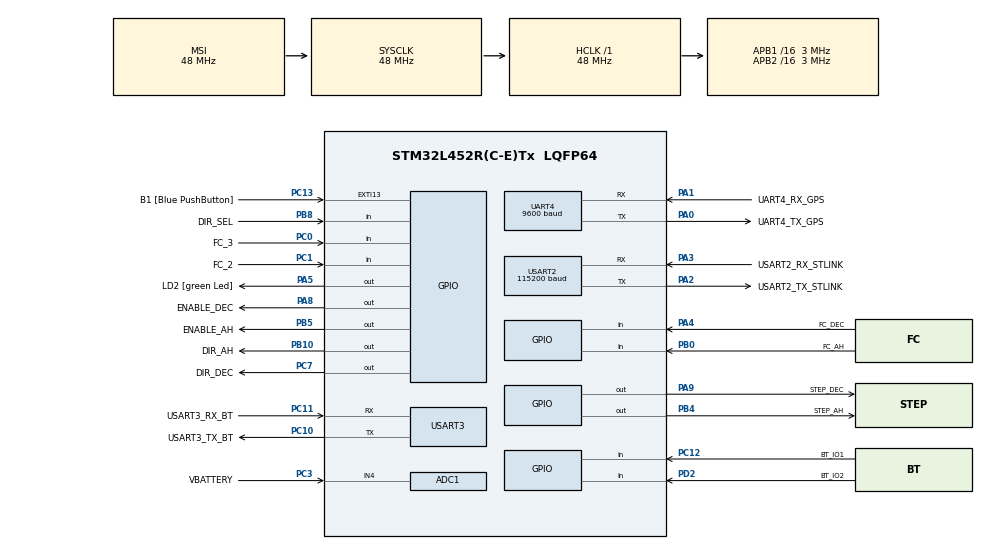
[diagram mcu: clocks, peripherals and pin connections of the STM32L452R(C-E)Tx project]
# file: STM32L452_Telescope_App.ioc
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ADC1.Channel-4\#ChannelRegularConversion=ADC_CHANNEL_4
ADC1.Channel-5\#ChannelRegularConversion=ADC_CHANNEL_TEMPSENSOR
ADC1.Channel-6\#ChannelRegularConversion=ADC_CHANNEL_VBAT
ADC1.Channel-7\#ChannelRegularConversion=ADC_CHANNEL_VREFINT
ADC1.ContinuousConvMode=DISABLE
ADC1.DMAContinuousRequests=DISABLE
ADC1.EOCSelection=ADC_EOC_SEQ_CONV
ADC1.NbrOfConversion=4
ADC1.NbrOfConversionFlag=1
ADC1.OffsetNumber-4\#ChannelRegularConversion=ADC_OFFSET_NONE
ADC1.OffsetNumber-5\#ChannelRegularConversion=ADC_OFFSET_NONE
ADC1.OffsetNumber-6\#ChannelRegularConversion=ADC_OFFSET_NONE
ADC1.OffsetNumber-7\#ChannelRegularConversion=ADC_OFFSET_NONE
ADC1.Rank-4\#ChannelRegularConversion=1
ADC1.Rank-5\#ChannelRegularConversion=2
ADC1.Rank-6\#ChannelRegularConversion=3
ADC1.Rank-7\#ChannelRegularConversion=4
ADC1.Resolution=ADC_RESOLUTION_12B
ADC1.SamplingTime-4\#ChannelRegularConversion=ADC_SAMPLETIME_640CYCLES_5
ADC1.SamplingTime-5\#ChannelRegularConversion=ADC_SAMPLETIME_92CYCLES_5
ADC1.SamplingTime-6\#ChannelRegularConversion=ADC_SAMPLETIME_92CYCLES_5
ADC1.SamplingTime-7\#ChannelRegularConversion=ADC_SAMPLETIME_92CYCLES_5
ADC1.master=1
Dma.ADC1.0.Direction=DMA_PERIPH_TO_MEMORY
Dma.ADC1.0.Instance=DMA1_Channel1
Dma.ADC1.0.MemDataAlignment=DMA_MDATAALIGN_HALFWORD
Dma.ADC1.0.MemInc=DMA_MINC_ENABLE
Dma.ADC1.0.Mode=DMA_CIRCULAR
Dma.ADC1.0.PeriphDataAlignment=DMA_PDATAALIGN_HALFWORD
Dma.ADC1.0.PeriphInc=DMA_PINC_DISABLE
Dma.ADC1.0.Priority=DMA_PRIORITY_LOW
Dma.Request0=ADC1
Mcu.Family=STM32L4
Mcu.Name=STM32L452R(C-E)Tx
Mcu.Package=LQFP64
NVIC.ADC1_IRQn=true\:0\:0\:false\:false\:true\:true\:true
NVIC.DMA1_Channel1_IRQn=true\:0\:0\:false\:false\:true\:false\:true
NVIC.PriorityGroup=NVIC_PRIORITYGROUP_4
NVIC.TIM1_BRK_TIM15_IRQn=true\:0\:0\:false\:false\:true\:true\:true
NVIC.TIM2_IRQn=true\:0\:0\:true\:false\:true\:true\:true
NVIC.UART4_IRQn=true\:3\:0\:true\:false\:true\:true\:true
NVIC.USART2_IRQn=true\:3\:0\:true\:false\:true\:true\:true
NVIC.USART3_IRQn=true\:0\:0\:false\:false\:true\:true\:true
NVIC.WWDG_IRQn=true\:0\:0\:false\:false\:true\:true\:true
PA0.GPIO_Label=UART4_TX_GPS
PA0.Mode=Asynchronous
PA0.Signal=UART4_TX
PA1.GPIO_Label=UART4_RX_GPS
PA1.Mode=Asynchronous
PA1.Signal=UART4_RX
PA13\ (JTMS/SWDIO).GPIO_Label=TMS
PA13\ (JTMS/SWDIO).Mode=Trace_Asynchronous_SW
PA13\ (JTMS/SWDIO).Signal=SYS_JTMS-SWDIO
PA14\ (JTCK/SWCLK).GPIO_Label=TCK
PA14\ (JTCK/SWCLK).Mode=Trace_Asynchronous_SW
PA14\ (JTCK/SWCLK).Signal=SYS_JTCK-SWCLK
PA2.GPIO_Label=USART2_TX_STLINK
PA2.GPIO_Mode=GPIO_MODE_AF_PP
PA2.GPIO_PuPd=GPIO_NOPULL
PA2.GPIO_Speed=GPIO_SPEED_FREQ_VERY_HIGH
PA2.Mode=Asynchronous
PA2.Signal=USART2_TX
PA3.GPIO_Label=USART2_RX_STLINK
PA3.GPIO_Mode=GPIO_MODE_AF_PP
PA3.GPIO_PuPd=GPIO_NOPULL
PA3.GPIO_Speed=GPIO_SPEED_FREQ_VERY_HIGH
PA3.Mode=Asynchronous
PA3.Signal=USART2_RX
PA4.GPIO_Label=FC_DEC
PA4.GPIO_PuPd=GPIO_PULLUP
PA4.Signal=GPIO_Input
PA5.GPIO_Label=LD2 [green Led]
PA5.GPIO_ModeDefaultOutputPP=GPIO_MODE_OUTPUT_PP
PA5.GPIO_PuPd=GPIO_NOPULL
PA5.GPIO_Speed=GPIO_SPEED_FREQ_LOW
PA5.Signal=GPIO_Output
PA8.GPIO_Label=ENABLE_DEC
PA8.Signal=GPIO_Output
PA9.GPIO_Label=STEP_DEC
PA9.Signal=GPIO_Output
PB0.GPIO_Label=FC_AH
PB0.GPIO_PuPd=GPIO_PULLUP
PB0.Signal=GPIO_Input
PB10.GPIO_Label=DIR_AH
PB10.Signal=GPIO_Output
PB3\ (JTDO/TRACESWO).GPIO_Label=SWO
PB3\ (JTDO/TRACESWO).Mode=Trace_Asynchronous_SW
PB3\ (JTDO/TRACESWO).Signal=SYS_JTDO-SWO
PB4\ (NJTRST).GPIO_Label=STEP_AH
PB4\ (NJTRST).Signal=GPIO_Output
PB5.GPIO_Label=ENABLE_AH
PB5.Signal=GPIO_Output
PB8.GPIO_Label=DIR_SEL
PB8.GPIO_PuPd=GPIO_PULLUP
PB8.Signal=GPIO_Input
PC0.GPIO_Label=FC_3
PC0.GPIO_PuPd=GPIO_PULLUP
PC0.Signal=GPIO_Input
PC1.GPIO_Label=FC_2
PC1.GPIO_PuPd=GPIO_PULLUP
PC1.Signal=GPIO_Input
PC10.GPIO_Label=USART3_TX_BT
PC10.Mode=Asynchronous
PC10.Signal=USART3_TX
PC11.GPIO_Label=USART3_RX_BT
PC11.Mode=Asynchronous
PC11.Signal=USART3_RX
PC12.GPIO_Label=BT_IO1
PC12.Signal=GPIO_Input
PC13.GPIO_Label=B1 [Blue PushButton]
PC13.GPIO_ModeDefaultEXTI=GPIO_MODE_IT_FALLING
PC13.GPIO_PuPd=GPIO_NOPULL
PC13.Signal=GPXTI13
PC14-OSC32_IN\ (PC14).Mode=LSE-External-Oscillator
PC14-OSC32_IN\ (PC14).Signal=RCC_OSC32_IN
PC15-OSC32_OUT\ (PC15).Mode=LSE-External-Oscillator
PC15-OSC32_OUT\ (PC15).Signal=RCC_OSC32_OUT
PC3.GPIO_Label=VBATTERY
PC3.Signal=ADCx_IN4
PC7.GPIO_Label=DIR_DEC
PC7.Signal=GPIO_Output
PD2.GPIO_Label=BT_IO2
PD2.Signal=GPIO_Input
PH0-OSC_IN\ (PH0).Signal=RCC_OSC_IN
PH1-OSC_OUT\ (PH1).Signal=RCC_OSC_OUT
ProjectManager.HeapSize=0x200
ProjectManager.StackSize=0x400
ProjectManager.TargetToolchain=SW4STM32
RCC.ADCFreq_Value=16000000
RCC.AHBFreq_Value=48000000
RCC.APB1CLKDivider=RCC_HCLK_DIV16
RCC.APB1Freq_Value=3000000
RCC.APB1TimFreq_Value=6000000
RCC.APB2CLKDivider=RCC_HCLK_DIV16
RCC.APB2Freq_Value=3000000
RCC.APB2TimFreq_Value=6000000
RCC.CortexFreq_Value=48000000
RCC.HCLKFreq_Value=48000000
RCC.HSE_VALUE=8000000
RCC.HSI48_VALUE=48000000
RCC.HSI_VALUE=16000000
RCC.MSIClockRange=RCC_MSIRANGE_11
RCC.MSI_VALUE=48000000
RCC.PLLR=RCC_PLLR_DIV8
RCC.PLLSAI1R=RCC_PLLR_DIV8
RCC.PLLSourceVirtual=RCC_PLLSOURCE_HSI
RCC.PREFETCH_ENABLE=1
RCC.RTCClockSelection=RCC_RTCCLKSOURCE_LSE
RCC.SYSCLKFreq_VALUE=48000000
RCC.USBFreq_Value=64000000
RCC.VCOOutputFreq_Value=128000000
RTC.Date=10
RTC.Format=RTC_FORMAT_BIN
RTC.Month=RTC_MONTH_DECEMBER
RTC.StoreOperation=RTC_STOREOPERATION_RESET
RTC.Year=18
SH.ADCx_IN4.0=ADC1_IN4,IN4-Single-Ended
TIM15.Channel-Output\ Compare1\ No\ Output=TIM_CHANNEL_1
TIM15.Channel-Output\ Compare2\ No\ Output=TIM_CHANNEL_2
TIM15.Period=65535
TIM15.Prescaler=6-1
TIM2.Channel-Output\ Compare1\ No\ Output=TIM_CHANNEL_1
TIM2.Period=4294967295
TIM2.Prescaler=6-1
UART4.BaudRate=9600
UART4.DMADisableonRxErrorParam=UART_ADVFEATURE_DMA_DISABLEONRXERROR
UART4.OverSampling=UART_OVERSAMPLING_16
UART4.OverrunDisableParam=UART_ADVFEATURE_OVERRUN_DISABLE
USART2.BaudRate=115200
USART2.DMADisableonRxErrorParam=ADVFEATURE_DMA_DISABLEONRXERROR
USART2.OverSampling=UART_OVERSAMPLING_16
USART2.OverrunDisableParam=ADVFEATURE_OVERRUN_DISABLE
USART2.VirtualMode-Asynchronous=VM_ASYNC
USART3.DMADisableonRxErrorParam=ADVFEATURE_DMA_DISABLEONRXERROR
USART3.OverrunDisableParam=ADVFEATURE_OVERRUN_DISABLE
USART3.VirtualMode-Asynchronous=VM_ASYNC
VP_ADC1_TempSens_Input.Mode=IN-TempSens
VP_ADC1_Vbat_Input.Mode=IN-Vbat
VP_ADC1_Vref_Input.Mode=IN-Vrefint
VP_RTC_VS_RTC_Activate.Mode=RTC_Enabled
VP_RTC_VS_RTC_Calendar.Mode=RTC_Calendar
VP_TIM15_VS_ClockSourceINT.Mode=Internal
VP_TIM15_VS_no_output1.Mode=Output Compare1 No Output
VP_TIM15_VS_no_output2.Mode=Output Compare2 No Output
VP_TIM2_VS_ClockSourceINT.Mode=Internal
VP_TIM2_VS_no_output1.Mode=Output Compare1 No Output
VP_WWDG_VS_WWDG.Mode=WWDG_Activate
WWDG.Prescaler=WWDG_PRESCALER_8
board=NUCLEO-L452RE

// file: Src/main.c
/* USER CODE BEGIN Header */
/**
  ******************************************************************************
  * @file           : main.c
  * @brief          : Main program body
  ******************************************************************************
  ** This notice applies to any and all portions of this file
  * that are not between comment pairs USER CODE BEGIN and
  * USER CODE END. Other portions of this file, whether
  * inserted by the user or by software development tools
  * are owned by their respective copyright owners.
  *
  * COPYRIGHT(c) 2019 STMicroelectronics
  *
  * Redistribution and use in source and binary forms, with or without modification,
  * are permitted provided that the following conditions are met:
  *   1. Redistributions of source code must retain the above copyright notice,
  *      this list of conditions and the following disclaimer.
  *   2. Redistributions in binary form must reproduce the above copyright notice,
  *      this list of conditions and the following disclaimer in the documentation
  *      and/or other materials provided with the distribution.
  *   3. Neither the name of STMicroelectronics nor the names of its contributors
  *      may be used to endorse or promote products derived from this software
  *      without specific prior written permission.
  *
  * THIS SOFTWARE IS PROVIDED BY THE COPYRIGHT HOLDERS AND CONTRIBUTORS "AS IS"
  * AND ANY EXPRESS OR IMPLIED WARRANTIES, INCLUDING, BUT NOT LIMITED TO, THE
  * IMPLIED WARRANTIES OF MERCHANTABILITY AND FITNESS FOR A PARTICULAR PURPOSE ARE
  * DISCLAIMED. IN NO EVENT SHALL THE COPYRIGHT HOLDER OR CONTRIBUTORS BE LIABLE
  * FOR ANY DIRECT, INDIRECT, INCIDENTAL, SPECIAL, EXEMPLARY, OR CONSEQUENTIAL
  * DAMAGES (INCLUDING, BUT NOT LIMITED TO, PROCUREMENT OF SUBSTITUTE GOODS OR
  * SERVICES; LOSS OF USE, DATA, OR PROFITS; OR BUSINESS INTERRUPTION) HOWEVER
  * CAUSED AND ON ANY THEORY OF LIABILITY, WHETHER IN CONTRACT, STRICT LIABILITY,
  * OR TORT (INCLUDING NEGLIGENCE OR OTHERWISE) ARISING IN ANY WAY OUT OF THE USE
  * OF THIS SOFTWARE, EVEN IF ADVISED OF THE POSSIBILITY OF SUCH DAMAGE.
  *
  ******************************************************************************
  */
/* USER CODE END Header */

#include "main.h"
#include "adc.h"
#include "dma.h"
#include "rtc.h"
#include "tim.h"
#include "usart.h"
#include "wwdg.h"
#include "gpio.h"

/* USER CODE BEGIN Includes */
#if 0
#include "printf_redirect.h"
#include "telescope_app.h"
#endif
#include "includes.h"
/* USER CODE END Includes */

/* USER CODE BEGIN PV */
/* Private variables ---------------------------------------------------------*/

/* USER CODE END PV */

void SystemClock_Config(void);
/* USER CODE BEGIN PFP */
/* Private function prototypes -----------------------------------------------*/

/* USER CODE END PFP */

int main(void)
{

  /* MCU Configuration--------------------------------------------------------*/

  /* Reset of all peripherals, Initializes the Flash interface and the Systick. */
  HAL_Init();

  /* Configure the system clock */
  SystemClock_Config();

  /* Initialize all configured peripherals */
  MX_GPIO_Init();
  MX_DMA_Init();
  MX_USART2_UART_Init();
  MX_UART4_Init();
  MX_TIM2_Init();
  MX_RTC_Init();
  MX_TIM15_Init();
  MX_USART3_UART_Init();
  MX_ADC1_Init();
  MX_WWDG_Init();
  /* USER CODE BEGIN 2 */

  //Demarrage du compteur de micro secondes.
  HAL_TIM_Base_Start(&htim2);

  Init_ITM();

  //Demarrage du process Telescope
  Telescope_init();

  Telescope_run();

  /* USER CODE END 2 */

  /* Infinite loop */
  while (1)
  {

  }
}

void SystemClock_Config(void)
{
  RCC_OscInitTypeDef RCC_OscInitStruct = {0};
  RCC_ClkInitTypeDef RCC_ClkInitStruct = {0};
  RCC_PeriphCLKInitTypeDef PeriphClkInit = {0};

  /** Configure LSE Drive Capability
  */
  HAL_PWR_EnableBkUpAccess();
  __HAL_RCC_LSEDRIVE_CONFIG(RCC_LSEDRIVE_LOW);
  /** Initializes the CPU, AHB and APB busses clocks
  */
  RCC_OscInitStruct.OscillatorType = RCC_OSCILLATORTYPE_HSI|RCC_OSCILLATORTYPE_LSE
                              |RCC_OSCILLATORTYPE_MSI;
  RCC_OscInitStruct.LSEState = RCC_LSE_ON;
  RCC_OscInitStruct.HSIState = RCC_HSI_ON;
  RCC_OscInitStruct.HSICalibrationValue = RCC_HSICALIBRATION_DEFAULT;
  RCC_OscInitStruct.MSIState = RCC_MSI_ON;
  RCC_OscInitStruct.MSICalibrationValue = 0;
  RCC_OscInitStruct.MSIClockRange = RCC_MSIRANGE_11;
  RCC_OscInitStruct.PLL.PLLState = RCC_PLL_NONE;
  if (HAL_RCC_OscConfig(&RCC_OscInitStruct) != HAL_OK)
  {
    Error_Handler();
  }
  /** Initializes the CPU, AHB and APB busses clocks
  */
  RCC_ClkInitStruct.ClockType = RCC_CLOCKTYPE_HCLK|RCC_CLOCKTYPE_SYSCLK
                              |RCC_CLOCKTYPE_PCLK1|RCC_CLOCKTYPE_PCLK2;
  RCC_ClkInitStruct.SYSCLKSource = RCC_SYSCLKSOURCE_MSI;
  RCC_ClkInitStruct.AHBCLKDivider = RCC_SYSCLK_DIV1;
  RCC_ClkInitStruct.APB1CLKDivider = RCC_HCLK_DIV16;
  RCC_ClkInitStruct.APB2CLKDivider = RCC_HCLK_DIV16;

  if (HAL_RCC_ClockConfig(&RCC_ClkInitStruct, FLASH_LATENCY_2) != HAL_OK)
  {
    Error_Handler();
  }
  PeriphClkInit.PeriphClockSelection = RCC_PERIPHCLK_RTC|RCC_PERIPHCLK_USART2
                              |RCC_PERIPHCLK_USART3|RCC_PERIPHCLK_UART4
                              |RCC_PERIPHCLK_ADC;
  PeriphClkInit.Usart2ClockSelection = RCC_USART2CLKSOURCE_PCLK1;
  PeriphClkInit.Usart3ClockSelection = RCC_USART3CLKSOURCE_PCLK1;
  PeriphClkInit.Uart4ClockSelection = RCC_UART4CLKSOURCE_PCLK1;
  PeriphClkInit.AdcClockSelection = RCC_ADCCLKSOURCE_PLLSAI1;
  PeriphClkInit.RTCClockSelection = RCC_RTCCLKSOURCE_LSE;
  PeriphClkInit.PLLSAI1.PLLSAI1Source = RCC_PLLSOURCE_HSI;
  PeriphClkInit.PLLSAI1.PLLSAI1M = 1;
  PeriphClkInit.PLLSAI1.PLLSAI1N = 8;
  PeriphClkInit.PLLSAI1.PLLSAI1P = RCC_PLLP_DIV7;
  PeriphClkInit.PLLSAI1.PLLSAI1Q = RCC_PLLQ_DIV2;
  PeriphClkInit.PLLSAI1.PLLSAI1R = RCC_PLLR_DIV8;
  PeriphClkInit.PLLSAI1.PLLSAI1ClockOut = RCC_PLLSAI1_ADC1CLK;
  if (HAL_RCCEx_PeriphCLKConfig(&PeriphClkInit) != HAL_OK)
  {
    Error_Handler();
  }
  /** Configure the main internal regulator output voltage
  */
  if (HAL_PWREx_ControlVoltageScaling(PWR_REGULATOR_VOLTAGE_SCALE1) != HAL_OK)
  {
    Error_Handler();
  }
  /** Enable MSI Auto calibration
  */
  HAL_RCCEx_EnableMSIPLLMode();
}

void Error_Handler(void)
{
  /* USER CODE BEGIN Error_Handler_Debug */
  /* User can add his own implementation to report the HAL error return state */
  while(1)
  {
	  HAL_NVIC_SystemReset();
  }
  /* USER CODE END Error_Handler_Debug */
}

/************************ (C) COPYRIGHT STMicroelectronics *****END OF FILE****/
